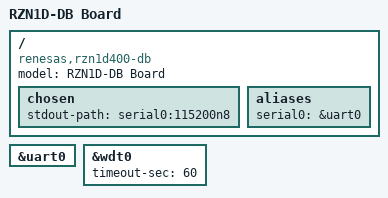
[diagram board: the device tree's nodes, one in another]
// SPDX-License-Identifier: GPL-2.0
/*
 * Device Tree Source for the RZN1D-DB Board
 *
 * Copyright (C) 2018 Renesas Electronics Europe Limited
 *
 */

/dts-v1/;

#include "r9a06g032.dtsi"

/ {
	model = "RZN1D-DB Board";
	compatible = "renesas,rzn1d400-db", "renesas,r9a06g032";

	chosen {
		stdout-path = "serial0:115200n8";
	};

	aliases {
		serial0 = &uart0;
	};
};

&uart0 {
	status = "okay";
};

&wdt0 {
	timeout-sec = <60>;
	status = "okay";
};
